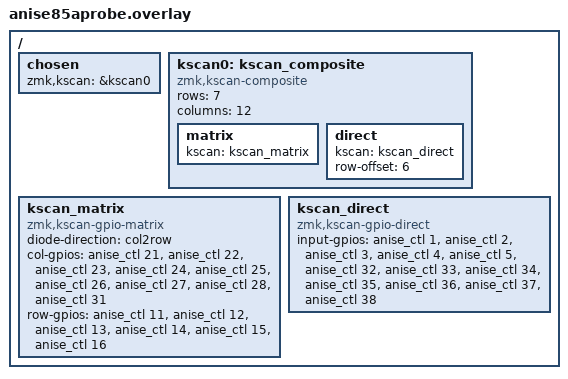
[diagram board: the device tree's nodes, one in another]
/*
 * Temporary probe, flashed on the anise85a RIGHT half as a standalone board
 * with USB logging. Rows 0-5: the right-half matrix exactly as
 * anise85a_right.overlay scans it (kscan columns 0-8 = keymap columns 7-15).
 * Row 6: every non-matrix anise_ctl pin, read directly with pull-downs.
 * Round 1 used pull-ups (encoder common to GND) and saw nothing; this round
 * catches a common tied to VCC or to a driven matrix column.
 *
 * Direct index -> anise_ctl pin:
 *   0:1 1:2 2:3 3:4 4:5 5:32 6:33 7:34 8:35 9:36 10:37 11:38
 * 2 (RGB data) and 38 (ext-power) are free here: no underglow, ext-power off.
 */

/ {
    chosen {
        zmk,kscan = &kscan0;
    };

    kscan0: kscan_composite {
        compatible = "zmk,kscan-composite";
        rows = <7>;
        columns = <12>;

        matrix {
            kscan = <&kscan_matrix>;
        };

        direct {
            kscan = <&kscan_direct>;
            row-offset = <6>;
        };
    };

    kscan_matrix: kscan_matrix {
        compatible = "zmk,kscan-gpio-matrix";
        diode-direction = "col2row";
        col-gpios
            = <&anise_ctl 21 GPIO_ACTIVE_HIGH>
            , <&anise_ctl 22 GPIO_ACTIVE_HIGH>
            , <&anise_ctl 23 GPIO_ACTIVE_HIGH>
            , <&anise_ctl 24 GPIO_ACTIVE_HIGH>
            , <&anise_ctl 25 GPIO_ACTIVE_HIGH>
            , <&anise_ctl 26 GPIO_ACTIVE_HIGH>
            , <&anise_ctl 27 GPIO_ACTIVE_HIGH>
            , <&anise_ctl 28 GPIO_ACTIVE_HIGH>
            , <&anise_ctl 31 GPIO_ACTIVE_HIGH>
            ;
        row-gpios
            = <&anise_ctl 11 (GPIO_ACTIVE_HIGH | GPIO_PULL_DOWN)>
            , <&anise_ctl 12 (GPIO_ACTIVE_HIGH | GPIO_PULL_DOWN)>
            , <&anise_ctl 13 (GPIO_ACTIVE_HIGH | GPIO_PULL_DOWN)>
            , <&anise_ctl 14 (GPIO_ACTIVE_HIGH | GPIO_PULL_DOWN)>
            , <&anise_ctl 15 (GPIO_ACTIVE_HIGH | GPIO_PULL_DOWN)>
            , <&anise_ctl 16 (GPIO_ACTIVE_HIGH | GPIO_PULL_DOWN)>
            ;
    };

    kscan_direct: kscan_direct {
        compatible = "zmk,kscan-gpio-direct";
        input-gpios
            = <&anise_ctl 1 (GPIO_ACTIVE_HIGH | GPIO_PULL_DOWN)>
            , <&anise_ctl 2 (GPIO_ACTIVE_HIGH | GPIO_PULL_DOWN)>
            , <&anise_ctl 3 (GPIO_ACTIVE_HIGH | GPIO_PULL_DOWN)>
            , <&anise_ctl 4 (GPIO_ACTIVE_HIGH | GPIO_PULL_DOWN)>
            , <&anise_ctl 5 (GPIO_ACTIVE_HIGH | GPIO_PULL_DOWN)>
            , <&anise_ctl 32 (GPIO_ACTIVE_HIGH | GPIO_PULL_DOWN)>
            , <&anise_ctl 33 (GPIO_ACTIVE_HIGH | GPIO_PULL_DOWN)>
            , <&anise_ctl 34 (GPIO_ACTIVE_HIGH | GPIO_PULL_DOWN)>
            , <&anise_ctl 35 (GPIO_ACTIVE_HIGH | GPIO_PULL_DOWN)>
            , <&anise_ctl 36 (GPIO_ACTIVE_HIGH | GPIO_PULL_DOWN)>
            , <&anise_ctl 37 (GPIO_ACTIVE_HIGH | GPIO_PULL_DOWN)>
            , <&anise_ctl 38 (GPIO_ACTIVE_HIGH | GPIO_PULL_DOWN)>
            ;
    };
};
